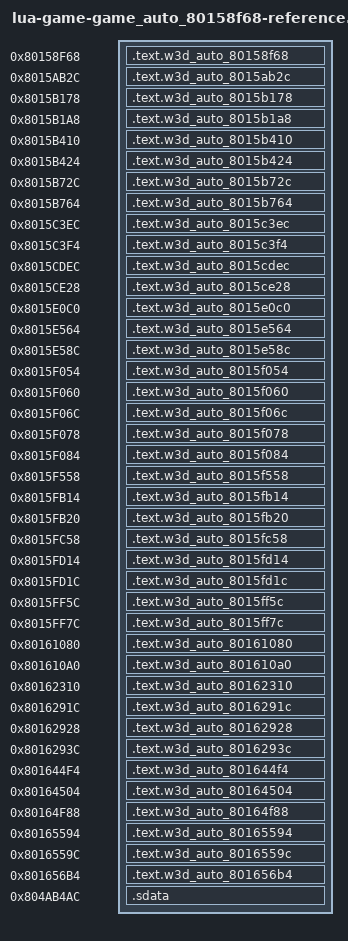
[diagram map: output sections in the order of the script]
/* Generated reference-only placements. All bodies are source-built. */
OUTPUT_FORMAT("elf32-powerpc")
OUTPUT_ARCH(powerpc)
ENTRY(w3d_auto_80158f68)
_SDA_BASE_ = 0x804b2540;
_SDA2_BASE_ = 0x804c2540;
fn_800FC7F8 = 0x800fc7f8;
fn_8015B78C = 0x8015b78c;
fn_8015B904 = 0x8015b904;
fn_8015B9D0 = 0x8015b9d0;
fn_8015CED4 = 0x8015ced4;
fn_8015CF14 = 0x8015cf14;
fn_8015E900 = 0x8015e900;
fn_8015F4C8 = 0x8015f4c8;
fn_8015FB34 = 0x8015fb34;
fn_801625DC = 0x801625dc;
fn_80162BA8 = 0x80162ba8;
fn_80162BC8 = 0x80162bc8;
fn_80162C20 = 0x80162c20;
fn_80162C40 = 0x80162c40;
fn_80163754 = 0x80163754;
fn_80164AA8 = 0x80164aa8;
fn_8016EED0 = 0x8016eed0;
fn_801FE1F8 = 0x801fe1f8;
fn_801FE45C = 0x801fe45c;
fn_802CAFD0 = 0x802cafd0;
fn_802CC5E0 = 0x802cc5e0;
fn_802CC8EC = 0x802cc8ec;
fn_802CCBB4 = 0x802ccbb4;
fn_802CD010 = 0x802cd010;
fn_8034B6D8 = 0x8034b6d8;
fn_8034BA50 = 0x8034ba50;
SECTIONS {
  .text.w3d_auto_80158f68 0x80158f68 : { *(.text.w3d_auto_80158f68) }
  .text.w3d_auto_8015ab2c 0x8015ab2c : { *(.text.w3d_auto_8015ab2c) }
  .text.w3d_auto_8015b178 0x8015b178 : { *(.text.w3d_auto_8015b178) }
  .text.w3d_auto_8015b1a8 0x8015b1a8 : { *(.text.w3d_auto_8015b1a8) }
  .text.w3d_auto_8015b410 0x8015b410 : { *(.text.w3d_auto_8015b410) }
  .text.w3d_auto_8015b424 0x8015b424 : { *(.text.w3d_auto_8015b424) }
  .text.w3d_auto_8015b72c 0x8015b72c : { *(.text.w3d_auto_8015b72c) }
  .text.w3d_auto_8015b764 0x8015b764 : { *(.text.w3d_auto_8015b764) }
  .text.w3d_auto_8015c3ec 0x8015c3ec : { *(.text.w3d_auto_8015c3ec) }
  .text.w3d_auto_8015c3f4 0x8015c3f4 : { *(.text.w3d_auto_8015c3f4) }
  .text.w3d_auto_8015cdec 0x8015cdec : { *(.text.w3d_auto_8015cdec) }
  .text.w3d_auto_8015ce28 0x8015ce28 : { *(.text.w3d_auto_8015ce28) }
  .text.w3d_auto_8015e0c0 0x8015e0c0 : { *(.text.w3d_auto_8015e0c0) }
  .text.w3d_auto_8015e564 0x8015e564 : { *(.text.w3d_auto_8015e564) }
  .text.w3d_auto_8015e58c 0x8015e58c : { *(.text.w3d_auto_8015e58c) }
  .text.w3d_auto_8015f054 0x8015f054 : { *(.text.w3d_auto_8015f054) }
  .text.w3d_auto_8015f060 0x8015f060 : { *(.text.w3d_auto_8015f060) }
  .text.w3d_auto_8015f06c 0x8015f06c : { *(.text.w3d_auto_8015f06c) }
  .text.w3d_auto_8015f078 0x8015f078 : { *(.text.w3d_auto_8015f078) }
  .text.w3d_auto_8015f084 0x8015f084 : { *(.text.w3d_auto_8015f084) }
  .text.w3d_auto_8015f558 0x8015f558 : { *(.text.w3d_auto_8015f558) }
  .text.w3d_auto_8015fb14 0x8015fb14 : { *(.text.w3d_auto_8015fb14) }
  .text.w3d_auto_8015fb20 0x8015fb20 : { *(.text.w3d_auto_8015fb20) }
  .text.w3d_auto_8015fc58 0x8015fc58 : { *(.text.w3d_auto_8015fc58) }
  .text.w3d_auto_8015fd14 0x8015fd14 : { *(.text.w3d_auto_8015fd14) }
  .text.w3d_auto_8015fd1c 0x8015fd1c : { *(.text.w3d_auto_8015fd1c) }
  .text.w3d_auto_8015ff5c 0x8015ff5c : { *(.text.w3d_auto_8015ff5c) }
  .text.w3d_auto_8015ff7c 0x8015ff7c : { *(.text.w3d_auto_8015ff7c) }
  .text.w3d_auto_80161080 0x80161080 : { *(.text.w3d_auto_80161080) }
  .text.w3d_auto_801610a0 0x801610a0 : { *(.text.w3d_auto_801610a0) }
  .text.w3d_auto_80162310 0x80162310 : { *(.text.w3d_auto_80162310) }
  .text.w3d_auto_8016291c 0x8016291c : { *(.text.w3d_auto_8016291c) }
  .text.w3d_auto_80162928 0x80162928 : { *(.text.w3d_auto_80162928) }
  .text.w3d_auto_8016293c 0x8016293c : { *(.text.w3d_auto_8016293c) }
  .text.w3d_auto_801644f4 0x801644f4 : { *(.text.w3d_auto_801644f4) }
  .text.w3d_auto_80164504 0x80164504 : { *(.text.w3d_auto_80164504) }
  .text.w3d_auto_80164f88 0x80164f88 : { *(.text.w3d_auto_80164f88) }
  .text.w3d_auto_80165594 0x80165594 : { *(.text.w3d_auto_80165594) }
  .text.w3d_auto_8016559c 0x8016559c : { *(.text.w3d_auto_8016559c) }
  .text.w3d_auto_801656b4 0x801656b4 : { *(.text.w3d_auto_801656b4) }
  .sdata 0x804ab4ac (NOLOAD) : {
    . = 0x0; lbl_804AB4AC = .;
    . = 0x4; lbl_804AB4B0 = .;
    . = 0x8; lbl_804AB4B4 = .;
    . = 0xc; lbl_804AB4B8 = .;
    . = 0x40; lbl_804AB4EC = .;
    . = 0x4bb0; lbl_804B005C = .;
    . = 0x4c24; lbl_804B00D0 = .;
    . = 0x62e0; lbl_804B178C = .;
    . = 0x63dc; lbl_804B1888 = .;
    . = 0x63e0; lbl_804B188C = .;
    . += 1; }
  /DISCARD/ : { *(.text*) *(.rodata*) *(.data*) *(.bss*) *(.sdata*) *(.sbss*) *(.comment) }
}
